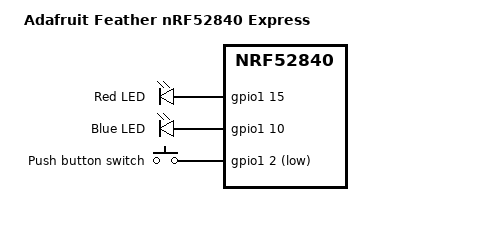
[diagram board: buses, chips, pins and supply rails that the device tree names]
/*
 * Copyright (c) 2020 Tobias Svehagen
 *
 * SPDX-License-Identifier: Apache-2.0
 */

/dts-v1/;

#include "adafruit_feather_nrf52840-common.dtsi"

/ {
	model = "Adafruit Feather nRF52840 Express";
	compatible = "adafruit,feather-nrf52840";

	chosen {
		zephyr,console = &cdc_acm_uart0;
		zephyr,shell-uart = &cdc_acm_uart0;
		zephyr,uart-mcumgr = &cdc_acm_uart0;
		zephyr,bt-mon-uart = &cdc_acm_uart0;
		zephyr,bt-c2h-uart = &cdc_acm_uart0;
		zephyr,sram = &sram0;
		zephyr,flash = &flash0;
		zephyr,code-partition = &slot0_partition;
		zephyr,ieee802154 = &ieee802154;
	};

	leds {
		compatible = "gpio-leds";
		led0: led_0 {
			gpios = <&gpio1 15 0>;
			label = "Red LED";
		};
		led1: led_1 {
			gpios = <&gpio1 10 0>;
			label = "Blue LED";
		};
	};

	buttons {
		compatible = "gpio-keys";
		button0: button_0 {
			gpios = <&gpio1 2 (GPIO_PULL_UP | GPIO_ACTIVE_LOW)>;
			label = "Push button switch";
			zephyr,code = <INPUT_KEY_0>;
		};
	};

	/* These aliases are provided for compatibility with samples */
	aliases {
		led0 = &led0;
		led1 = &led1;
		sw0 = &button0;
		watchdog0 = &wdt0;
		spi-flash0 = &gd25q16;
	};
};
